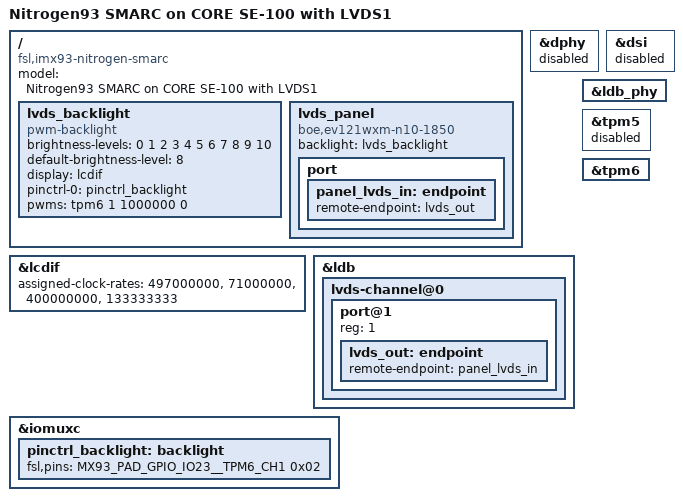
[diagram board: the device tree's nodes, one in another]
// SPDX-License-Identifier: (GPL-2.0-or-later OR MIT)
/*
 * Copyright 2024 Boundary Devices
 */

/dts-v1/;

#include "imx93-nitrogen-smarc.dts"

/ {
	model = "Nitrogen93 SMARC on CORE SE-100 with LVDS1";
	compatible = "fsl,imx93-nitrogen-smarc", "fsl,imx93";

	lvds_backlight: lvds_backlight {
		brightness-levels = <0 1 2 3 4 5 6 7 8 9 10>;
		compatible = "pwm-backlight";
		default-brightness-level = <8>;
		display = <&lcdif>;
		pinctrl-names = "default";
		pinctrl-0 = <&pinctrl_backlight>;
		pwms = <&tpm6 1 1000000 0>; /* 1 kHz */
	};

	lvds_panel {
		compatible = "boe,ev121wxm-n10-1850";
		backlight = <&lvds_backlight>;

		port {
			panel_lvds_in: endpoint {
				remote-endpoint = <&lvds_out>;
			};
		};
	};
};

&dphy {
	status = "disabled";
};

&dsi {
	status = "disabled";
};

&lcdif {
	assigned-clock-rates = <497000000>, <71000000>, <400000000>, <133333333>;
	status = "okay";
};

&ldb {
	status = "okay";

	lvds-channel@0 {
		status = "okay";

		port@1 {
			reg = <1>;

			lvds_out: endpoint {
				remote-endpoint = <&panel_lvds_in>;
			};
		};
	};

};

&ldb_phy {
	status = "okay";
};

&dphy {
	status = "disabled"; /* DSI */
};

&tpm5 {
	status = "disabled"; /* DSI backlight */
};

&tpm6 {
	status = "okay";
};

&iomuxc {
	pinctrl_backlight: backlight {
		fsl,pins = <
			MX93_PAD_GPIO_IO23__TPM6_CH1				0x02
		>;
	};
};
